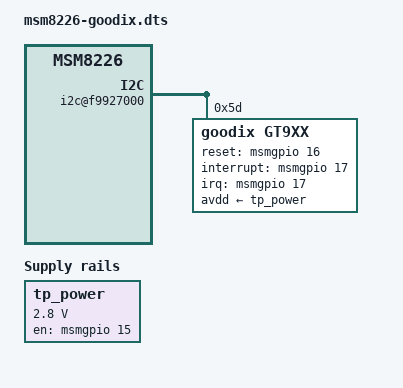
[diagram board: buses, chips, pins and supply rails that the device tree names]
/* Copyright (c) 2013, The Linux Foundation. All rights reserved.
 *
 * This program is free software; you can redistribute it and/or modify
 * it under the terms of the GNU General Public License version 2 and
 * only version 2 as published by the Free Software Foundation.
 *
 * This program is distributed in the hope that it will be useful,
 * but WITHOUT ANY WARRANTY; without even the implied warranty of
 * MERCHANTABILITY or FITNESS FOR A PARTICULAR PURPOSE.  See the
 * GNU General Public License for more details.
 */

&soc {
	tp_power: regulator-tp {
		compatible = "regulator-fixed";
		regulator-name = "tp_power";
		regulator-min-microvolt = <2800000>;
		regulator-max-microvolt = <2800000>;
		gpio = <&msmgpio 15 0>;
		startup-delay-us = <20000>;
		enable-active-high;
	};
	
	i2c@f9927000 {
		goodix@5d {
			compatible = "goodix,gt9xx";
			reg = <0x5d>;
			interrupt-parent = <&msmgpio>;
			interrupts = <17 0x2008>;
			reset-gpios = <&msmgpio 16 0x00>;
			interrupt-gpios = <&msmgpio 17 0x00>;
			avdd-supply = <&tp_power>;
			goodix,panel-coords = <0 0 720 1200>;
			goodix,display-coords = <0 0 720 1080>;
			goodix,button-map= <158 102 139>;
			goodix,product-id = "915";
			goodix,cfg-data0 = [
				41 D0 02 00 05 05 35 01 01 0F
				2D 06 50 32 03 05 00 00 00 00
				00 00 05 18 1A 1E 14 8C 0E 0E
				3F 3D 2A 09 00 00 00 99 04 1D
				00 00 00 00 00 00 00 00 00 00
				00 32 6E 94 D5 01 05 00 00 04
				CE 36 00 B5 3F 00 9E 4A 00 8B
				57 00 7C 65 00 7C 10 38 68 00
				56 50 35 66 66 27 00 00 00 00
				00 00 00 00 00 00 00 00 00 00
				00 00 00 00 00 00 00 00 00 00
				00 00 02 04 06 08 0A 0C 0E 10
				12 14 16 18 1A 1C 00 00 00 00
				00 00 00 00 00 00 00 00 00 00
				00 00 00 02 04 06 08 0A 0C 0F
				10 12 13 14 16 18 1C 1D 1E 1F
				20 21 22 24 26 28 29 2A 00 00
				00 FF FF FF FF FF FF FF FF FF
				FF FF FF FF A3 01];
			goodix,cfg-data1 = [
				41 D0 02 00 05 05 35 01 01 C3
				2D 06 55 32 03 03 00 00 00 00
				00 00 05 0A 0C 0F 0A 8C 0E 0E
				30 2E B8 08 00 00 00 8F 03 1D
				00 00 00 00 00 00 00 00 00 00
				00 2D 62 94 D5 02 05 00 00 04
				96 30 00 80 39 00 71 42 00 63
				4D 00 56 5A 00 56 10 38 68 00
				56 50 35 AA AA 27 00 00 00 00
				00 01 1B 14 0C 14 00 00 01 00
				00 00 00 00 00 00 00 00 00 00
				00 00 02 04 06 08 0A 0C 0E 10
				12 14 16 18 1A 1C FF FF FF FF
				FF FF FF FF FF FF FF FF FF FF
				FF FF 00 02 04 06 08 0A 0C 0F
				10 12 13 14 16 18 1C 1D 1E 1F
				20 21 22 24 26 28 29 2A FF FF
				FF FF FF FF FF FF FF FF FF FF
				FF FF FF FF 3E 01];
		};
	};
};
